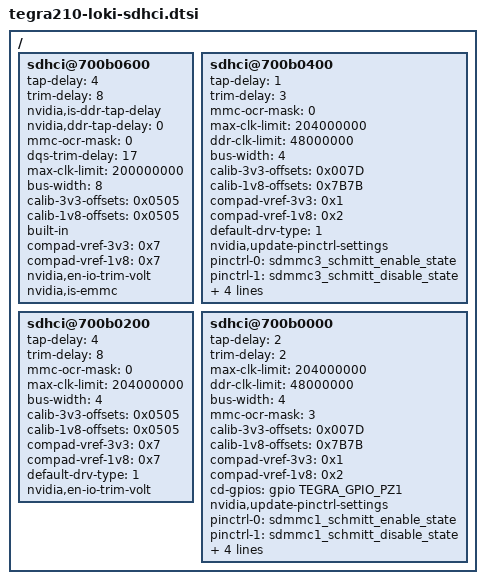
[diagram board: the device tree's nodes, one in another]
/*
 * Copyright (c) 2014, NVIDIA CORPORATION.  All rights reserved.
 *
 * This program is free software; you can redistribute it and/or modify
 * it under the terms of the GNU General Public License as published by
 * the Free Software Foundation; either version 2 of the License, or
 * (at your option) any later version.
 *
 * This program is distributed in the hope that it will be useful, but WITHOUT
 * ANY WARRANTY; without even the implied warranty of MERCHANTABILITY or
 * FITNESS FOR A PARTICULAR PURPOSE.  See the GNU General Public License for
 * more details.
 *
 * You should have received a copy of the GNU General Public License along
 * with this program; if not, write to the Free Software Foundation, Inc.,
 * 51 Franklin Street, Fifth Floor, Boston, MA  02110-1301, USA.
 */

/ {
	sdhci@700b0600 { /* SDMMC4 for EMMC on loki */
		tap-delay = <4>;
		trim-delay = <8>;
		nvidia,is-ddr-tap-delay;
		nvidia,ddr-tap-delay = <0>;
		mmc-ocr-mask = <0>;
		dqs-trim-delay = <17>;
		max-clk-limit = <200000000>;
		bus-width = <8>;
		calib-3v3-offsets = <0x0505>;
		calib-1v8-offsets = <0x0505>;
		built-in;
		compad-vref-3v3 = <0x7>;
		compad-vref-1v8 = <0x7>;
		nvidia,en-io-trim-volt;
		nvidia,is-emmc;
	};

	sdhci@700b0400 { /* SDMMC3 for 2nd Wifi on loki */
		tap-delay = <1>; /* SDMMC3 no stuff for Full size SD on foster */
		trim-delay = <3>;
		mmc-ocr-mask = <0>;
		max-clk-limit = <204000000>;
		ddr-clk-limit = <48000000>;
		bus-width = <4>;
		calib-3v3-offsets = <0x007D>;
		calib-1v8-offsets = <0x7B7B>;
		compad-vref-3v3 = <0x1>;
		compad-vref-1v8 = <0x2>;
		default-drv-type = <1>;
		nvidia,update-pinctrl-settings;
		pinctrl-names = "sdmmc_schmitt_enable", "sdmmc_schmitt_disable", "sdmmc_clk_schmitt_enable", "sdmmc_clk_schmitt_disable";
		pinctrl-0 = <&sdmmc3_schmitt_enable_state>;
		pinctrl-1 = <&sdmmc3_schmitt_disable_state>;
		pinctrl-2 = <&sdmmc3_clk_schmitt_enable_state>;
		pinctrl-3 = <&sdmmc3_clk_schmitt_disable_state>;
		nvidia,en-io-trim-volt;
		nvidia,update-pinctrl-settings;
		nvidia,enable-ext-loopback;
	};

	sdhci@700b0200 { /* SDMMC2 for Wifi on loki */
		tap-delay = <4>;
		trim-delay = <8>;
		mmc-ocr-mask = <0>;
		max-clk-limit = <204000000>;
		bus-width = <4>;
		calib-3v3-offsets = <0x0505>;
		calib-1v8-offsets = <0x0505>;
		compad-vref-3v3 = <0x7>;
		compad-vref-1v8 = <0x7>;
		default-drv-type = <1>;
		nvidia,en-io-trim-volt;
	};

	sdhci@700b0000 { /* SDMMC1 for uSD card on loki */
		tap-delay = <2>;
		trim-delay = <2>;
		max-clk-limit = <204000000>;
		ddr-clk-limit = <48000000>;
		bus-width = <4>;
		mmc-ocr-mask = <3>;
		calib-3v3-offsets = <0x007D>;
		calib-1v8-offsets = <0x7B7B>;
		compad-vref-3v3 = <0x1>;
		compad-vref-1v8 = <0x2>;
		cd-gpios = <&gpio TEGRA_GPIO_PZ1 0>;
		nvidia,update-pinctrl-settings;
		pinctrl-names = "sdmmc_schmitt_enable", "sdmmc_schmitt_disable", "sdmmc_clk_schmitt_enable", "sdmmc_clk_schmitt_disable";
		pinctrl-0 = <&sdmmc1_schmitt_enable_state>;
		pinctrl-1 = <&sdmmc1_schmitt_disable_state>;
		pinctrl-2 = <&sdmmc1_clk_schmitt_enable_state>;
		pinctrl-3 = <&sdmmc1_clk_schmitt_disable_state>;
		nvidia,en-io-trim-volt;
		nvidia,update-pinctrl-settings;
		nvidia,limit-vddio-max-volt;
	};
};
